# FM33FK5XX register map
File version: 1.0
CPU: Cortex-M33 r1p0, little endian, MPU, FPU, 3 interrupt priority bits
Registers are 32-bit, read-write, reset 0x0 unless marked. A register's access mark holds for its fields unless they carry their own. Offsets are from the block's base; [hi:lo] are bit positions; {n}, {i} and the like mark numbered series.

## ADC — ADC module information
Base 0x4001AC00
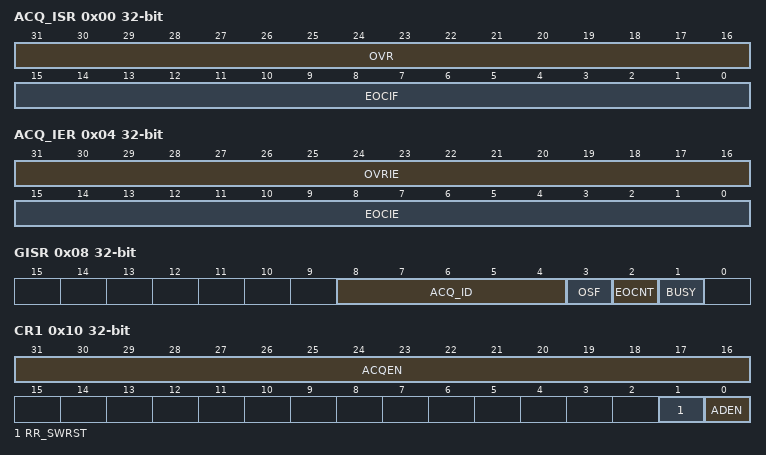
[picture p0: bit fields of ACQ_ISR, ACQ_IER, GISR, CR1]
0x00 ACQ_ISR
  [31:16] OVR — OVR field description
  [15:0] EOCIF — EOCIF field description
0x04 ACQ_IER
  [31:16] OVRIE — OVRIE field description
  [15:0] EOCIE — EOCIE field description
0x08 GISR
  [8:4] ACQ_ID — ACQ_ID field description
  [3] OSF — OSF field description
  [2] EOCNT — EOCNT field description
  [1] BUSY — BUSY field description
0x0C GIER
  [2] EOCNT — EOCNT field description
0x10 CR1
  [31:16] ACQEN — ACQEN field description
  [1] RR_SWRST — RR_SWRST field description
  [0] ADEN — ADEN field description
0x14 CR2 wo
  [15:0] SWTRIG — SWTRIG field description
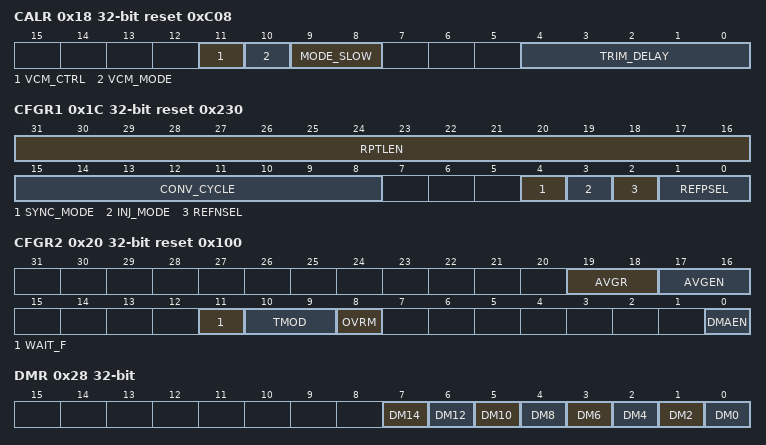
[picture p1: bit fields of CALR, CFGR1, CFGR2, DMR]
0x18 CALR reset 0xC08
  [11] VCM_CTRL — VCM_CTRL field description
  [10] VCM_MODE — VCM_MODE field description
  [9:8] MODE_SLOW — MODE_SLOW field description
  [4:0] TRIM_DELAY — TRIM_DELAY field description
0x1C CFGR1 reset 0x230
  [31:16] RPTLEN — RPTLEN field description
  [15:8] CONV_CYCLE — CONV_CYCLE field description
  [4] SYNC_MODE — SYNC_MODE field description
  [3] INJ_MODE — INJ_MODE field description
  [2] REFNSEL — REFNSEL field description
  [1:0] REFPSEL — REFPSEL field description
0x20 CFGR2 reset 0x100
  [19:18] AVGR — AVGR field description
  [17:16] AVGEN — AVGEN field description
  [11] WAIT_F — WAIT_F field description
  [10:9] TMOD — TMOD field description
  [8] OVRM — OVRM field description
  [0] DMAEN — DMAEN field description
0x24 PRICR
  [3:0] INJC — INJC field description
0x28 DMR
  [7] DM14 — DM14 field description
  [6] DM12 — DM12 field description
  [5] DM10 — DM10 field description
  [4] DM8 — DM8 field description
  [3] DM6 — DM6 field description
  [2] DM4 — DM4 field description
  [1] DM2 — DM2 field description
  [0] DM0 — DM0 field description
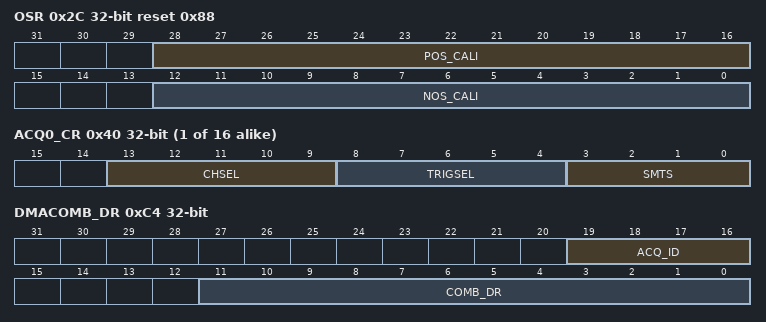
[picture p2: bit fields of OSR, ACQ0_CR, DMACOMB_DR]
0x2C OSR reset 0x88
  [28:16] POS_CALI — POS_CALI field description
  [12:0] NOS_CALI — NOS_CALI field description
0x30 ACQ_SR ro
  [15:0] REQ — REQ field description
{0x40+4i} ACQ{i}_CR (i=0..15)
  [13:9] CHSEL — CHSEL field description
  [8:4] TRIGSEL — TRIGSEL field description
  [3:0] SMTS — SMTS field description
{0x80+4i} ACQ{i}_DR ro (i=0..15)
  [11:0] RESULT — RESULT field description
0xC0 DMACOMB_CR ro
  [15:0] COMB_ACQEN — COMB_ACQEN field description
0xC4 DMACOMB_DR ro
  [19:16] ACQ_ID — ACQ_ID field description
  [11:0] COMB_DR — COMB_DR field description

## DAC0 — DAC0 module information
Base 0x40021800
Same registers: DAC1 0x40021C00
0x00 CR1 — DAC0ControlRegister
  [0] EN — EN field description
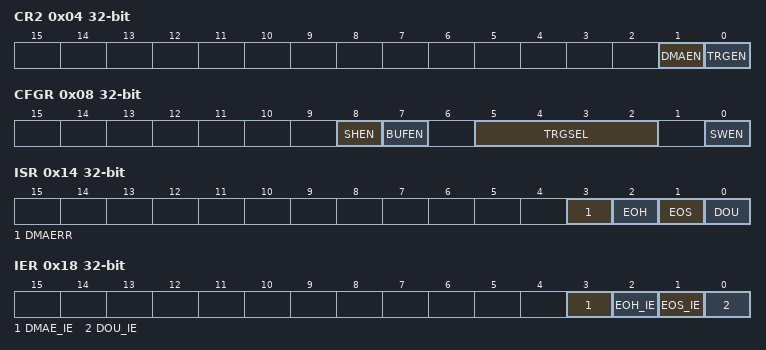
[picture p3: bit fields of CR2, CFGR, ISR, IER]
0x04 CR2 — DAC0ControlRegister
  [1] DMAEN — DMAEN field description
  [0] TRGEN — TRGEN field description
0x08 CFGR — DAC0ConfigRegister
  [8] SHEN — SHEN field description
  [7] BUFEN — BUFEN field description
  [5:2] TRGSEL — TRGSEL field description
  [0] SWEN — SWEN field description
0x0C SWTRGR wo — DAC0SoftwareTriggerRegister
  [0] SWTRIG — SWTRIG field description
0x10 DHR — DAC0DataHoldingRegister
  [11:0] DHR — DHR field description
0x14 ISR — DAC0InterruptStatusRegister
  [3] DMAERR — DMAERR field description
  [2] EOH — EOH field description
  [1] EOS — EOS field description
  [0] DOU — DOU field description
0x18 IER — DAC0InterruptEnableRegister
  [3] DMAE_IE — DMAE_IE field description
  [2] EOH_IE — EOH_IE field description
  [1] EOS_IE — EOS_IE field description
  [0] DOU_IE — DOU_IE field description
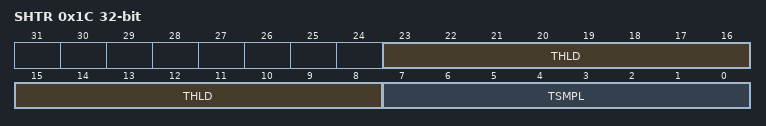
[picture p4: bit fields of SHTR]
0x1C SHTR — DAC0SampleHoldTimeRegister
  [23:8] THLD — THLD field description
  [7:0] TSMPL — TSMPL field description

## OPA0 — OPA0 module information
Base 0x40022800
Same registers: OPA1 0x40022820
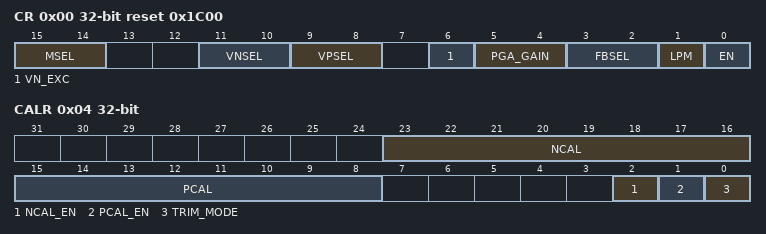
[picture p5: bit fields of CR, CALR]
0x00 CR reset 0x1C00 — OPA0ControlRegister
  [15:14] MSEL — MSEL field description
  [11:10] VNSEL — VNSEL field description
  [9:8] VPSEL — VPSEL field description
  [6] VN_EXC — VN_EXC field description
  [5:4] PGA_GAIN — PGA_GAIN field description
  [3:2] FBSEL — FBSEL field description
  [1] LPM — LPM field description
  [0] EN — EN field description
0x04 CALR — OPA0CalibrationRegister
  [23:16] NCAL — NCAL field description
  [15:8] PCAL — PCAL field description
  [2] NCAL_EN — NCAL_EN field description
  [1] PCAL_EN — PCAL_EN field description
  [0] TRIM_MODE — TRIM_MODE field description
0x08 COR ro — OPA0CalibrationOutputRegister
  [0] OUT — OUT field description
